// Create by TSMaster

VERSION ""

NS_ :

BS_:

BU_: Multiplexed

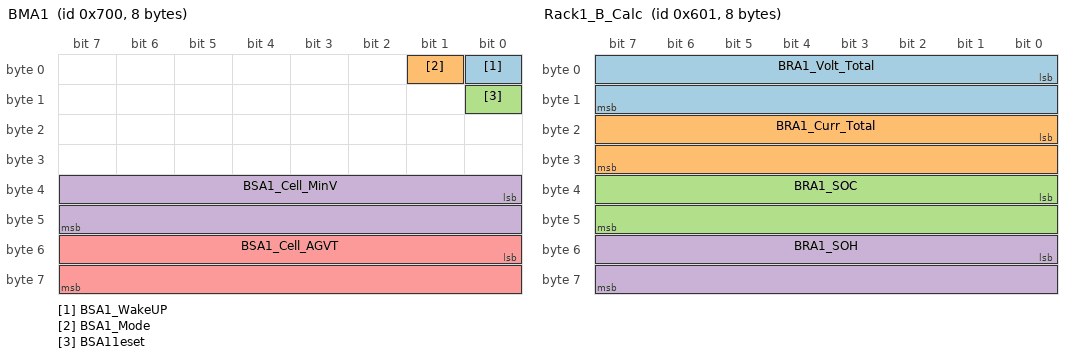
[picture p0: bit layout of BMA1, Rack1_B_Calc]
BO_ 1792 BMA1: 8 Vector__XXX
 SG_ BSA1_WakeUP : 0|1@1+ (1.0,0) [0.0|1.0] "" Vector__XXX
 SG_ BSA1_Mode : 1|1@1+ (1.0,0) [0.0|1.0] "" Vector__XXX
 SG_ BSA11eset : 8|1@1+ (1.0,0) [0.0|1.0] "" Vector__XXX
 SG_ BSA1_Cell_MinV : 32|16@1+ (0.001,0) [2.8|4.5] "" Vector__XXX
 SG_ BSA1_Cell_AGVT : 48|16@1- (0.1,0) [-40.0|100.0] "" Vector__XXX

BO_ 1537 Rack1_B_Calc: 8 Vector__XXX
 SG_ BRA1_Volt_Total : 0|16@1+ (0.1,0) [400.0|800.0] "" Vector__XXX
 SG_ BRA1_Curr_Total : 16|16@1- (0.1,0) [-500.0|500.0] "" Vector__XXX
 SG_ BRA1_SOC : 32|16@1+ (0.1,0) [0.0|120.0] "" Vector__XXX
 SG_ BRA1_SOH : 48|16@1+ (0.1,0) [0.0|100.0] "" Vector__XXX

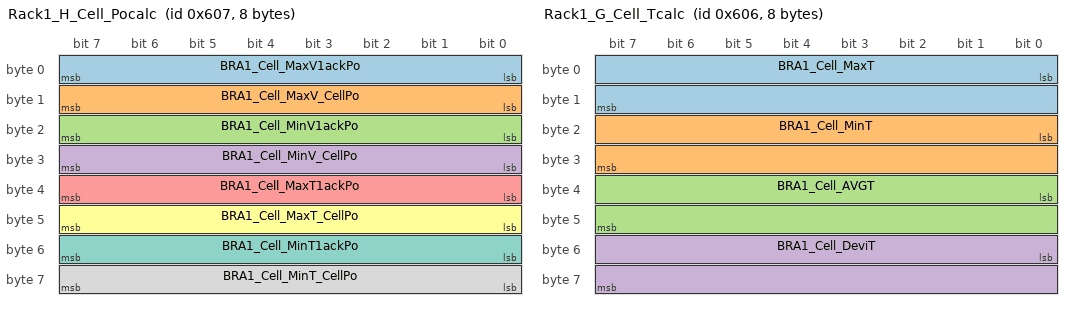
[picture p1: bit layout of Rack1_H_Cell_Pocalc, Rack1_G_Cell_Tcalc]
BO_ 1543 Rack1_H_Cell_Pocalc: 8 Vector__XXX
 SG_ BRA1_Cell_MaxV1ackPo : 0|8@1+ (1.0,0) [1.0|4.0] "" Vector__XXX
 SG_ BRA1_Cell_MaxV_CellPo : 8|8@1+ (1.0,0) [1.0|168.0] "" Vector__XXX
 SG_ BRA1_Cell_MinV1ackPo : 16|8@1+ (1.0,0) [1.0|4.0] "" Vector__XXX
 SG_ BRA1_Cell_MinV_CellPo : 24|8@1+ (1.0,0) [1.0|168.0] "" Vector__XXX
 SG_ BRA1_Cell_MaxT1ackPo : 32|8@1+ (1.0,0) [1.0|4.0] "" Vector__XXX
 SG_ BRA1_Cell_MaxT_CellPo : 40|8@1+ (1.0,0) [1.0|168.0] "" Vector__XXX
 SG_ BRA1_Cell_MinT1ackPo : 48|8@1+ (1.0,0) [1.0|4.0] "" Vector__XXX
 SG_ BRA1_Cell_MinT_CellPo : 56|8@1+ (1.0,0) [1.0|168.0] "" Vector__XXX

BO_ 1542 Rack1_G_Cell_Tcalc: 8 Vector__XXX
 SG_ BRA1_Cell_MaxT : 0|16@1- (0.1,0) [-40.0|100.0] "" Vector__XXX
 SG_ BRA1_Cell_MinT : 16|16@1- (0.1,0) [-40.0|100.0] "" Vector__XXX
 SG_ BRA1_Cell_AVGT : 32|16@1- (0.1,0) [-40.0|100.0] "" Vector__XXX
 SG_ BRA1_Cell_DeviT : 48|16@1+ (0.1,0) [-40.0|100.0] "" Vector__XXX

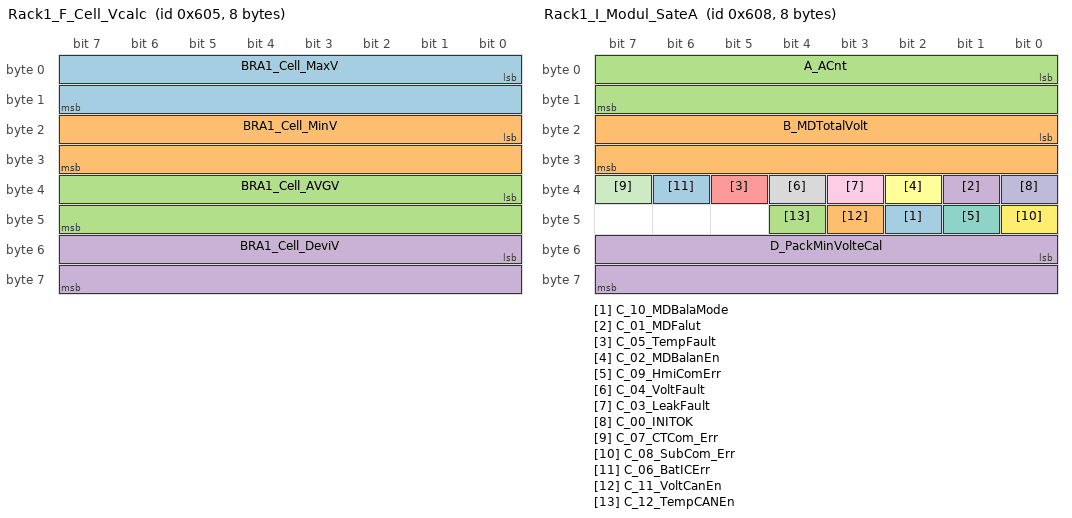
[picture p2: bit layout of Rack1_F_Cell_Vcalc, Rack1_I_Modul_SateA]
BO_ 1541 Rack1_F_Cell_Vcalc: 8 Vector__XXX
 SG_ BRA1_Cell_MaxV : 0|16@1+ (0.001,0) [2.8|4.5] "" Vector__XXX
 SG_ BRA1_Cell_MinV : 16|16@1+ (0.001,0) [2.8|4.5] "" Vector__XXX
 SG_ BRA1_Cell_AVGV : 32|16@1+ (0.001,0) [2.8|4.5] "" Vector__XXX
 SG_ BRA1_Cell_DeviV : 48|16@1+ (1.0,0) [0.0|500.0] "" Vector__XXX

BO_ 1544 Rack1_I_Modul_SateA: 8 Vector__XXX
 SG_ C_10_MDBalaMode : 42|1@1+ (0.1,0) [0|1] "F" Vector__XXX
 SG_ B_MDTotalVolt : 16|16@1+ (0.1,0) [40|100] "V" Vector__XXX
 SG_ A_ACnt : 0|16@1+ (1,0) [0|20] "Cnt" Vector__XXX
 SG_ C_01_MDFalut : 33|1@1+ (1,0) [0.0|1.0] "F" Vector__XXX
 SG_ C_05_TempFault : 37|1@1+ (1,0) [0.0|1.0] "F" Vector__XXX
 SG_ C_02_MDBalanEn : 34|1@1+ (1,0) [0.0|1.0] "F" Vector__XXX
 SG_ C_09_HmiComErr : 41|1@1+ (1,0) [0.0|1.0] "F" Vector__XXX
 SG_ C_04_VoltFault : 36|1@1+ (1,0) [0.0|1.0] "F" Vector__XXX
 SG_ C_03_LeakFault : 35|1@1+ (1,0) [0.0|1.0] "F" Vector__XXX
 SG_ C_00_INITOK : 32|1@1+ (1,0) [0.0|1] "F" Vector__XXX
 SG_ C_07_CTCom_Err : 39|1@1+ (1,0) [0.0|1.0] "F" Vector__XXX
 SG_ C_08_SubCom_Err : 40|1@1+ (1,0) [0.0|1.0] "F" Vector__XXX
 SG_ C_06_BatICErr : 38|1@1+ (1,0) [0|1] "F" Vector__XXX
 SG_ C_11_VoltCanEn : 43|1@1+ (1,0) [0|0] "F" Vector__XXX
 SG_ C_12_TempCANEn : 44|1@1+ (1,0) [0|1] "F" Vector__XXX
 SG_ D_PackMinVolteCal : 48|16@1+ (0.001,0) [2.8|4.8] "V" Vector__XXX

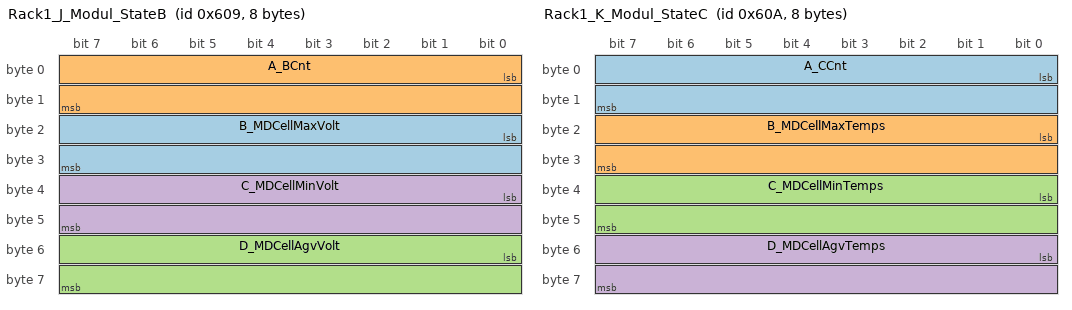
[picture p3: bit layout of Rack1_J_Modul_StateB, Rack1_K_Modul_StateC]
BO_ 1545 Rack1_J_Modul_StateB: 8 Vector__XXX
 SG_ B_MDCellMaxVolt : 16|16@1+ (0.001,0) [2.8|4.5] "V" Vector__XXX
 SG_ A_BCnt : 0|16@1+ (1,0) [0|20] "Cnt" Vector__XXX
 SG_ D_MDCellAgvVolt : 48|16@1+ (0.001,0) [2.8|4.5] "V" Vector__XXX
 SG_ C_MDCellMinVolt : 32|16@1+ (0.001,0) [2.8|4.5] "V" Vector__XXX

BO_ 1546 Rack1_K_Modul_StateC: 8 Vector__XXX
 SG_ A_CCnt : 0|16@1+ (1,0) [0|20] "Cnt" Vector__XXX
 SG_ B_MDCellMaxTemps : 16|16@1- (0.1,0) [-30|65] "deg" Vector__XXX
 SG_ C_MDCellMinTemps : 32|16@1- (0.1,0) [-30|0] "deg" Vector__XXX
 SG_ D_MDCellAgvTemps : 48|16@1- (0.1,0) [-30|65] "deg" Vector__XXX

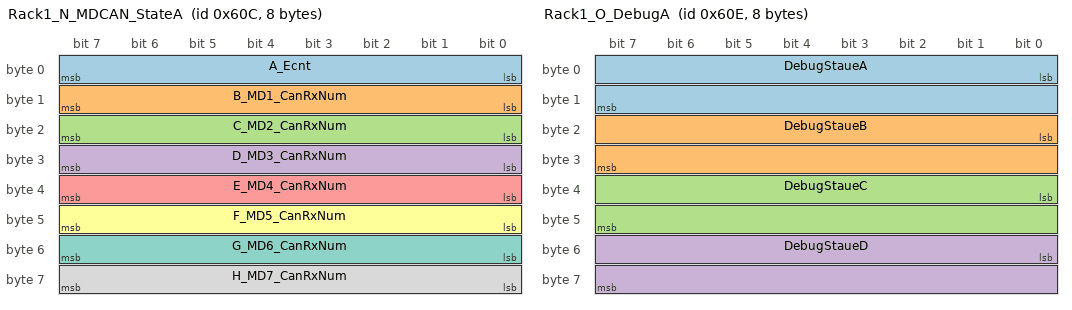
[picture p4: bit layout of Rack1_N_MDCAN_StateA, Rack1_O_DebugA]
BO_ 1548 Rack1_N_MDCAN_StateA: 8 Vector__XXX
 SG_ A_Ecnt : 0|8@1+ (1,0) [0|20] "Cnt" Vector__XXX
 SG_ B_MD1_CanRxNum : 8|8@1+ (1,0) [0|200] "Cnt" Vector__XXX
 SG_ C_MD2_CanRxNum : 16|8@1+ (1,0) [0|200] "Cnt" Vector__XXX
 SG_ D_MD3_CanRxNum : 24|8@1+ (1,0) [0|200] "Cnt" Vector__XXX
 SG_ E_MD4_CanRxNum : 32|8@1+ (1,0) [0|200] "Cnt" Vector__XXX
 SG_ F_MD5_CanRxNum : 40|8@1+ (1,0) [0|200] "Cnt" Vector__XXX
 SG_ G_MD6_CanRxNum : 48|8@1+ (1,0) [0|200] "Cnt" Vector__XXX
 SG_ H_MD7_CanRxNum : 56|8@1+ (1,0) [0|200] "Cnt" Vector__XXX

BO_ 1549 Rack1_N_MDCAN_StateB: 8 Vector__XXX
 SG_ A_Maincount : 0|16@1+ (1,0) [0|3000] "Cnt" Vector__XXX
 SG_ B_MainIsr1 : 16|16@1+ (1,0) [0|3000] "Cnt" Vector__XXX
 SG_ C_CTCanRx : 32|19@1+ (1,0) [0|3000] "Cnt" Vector__XXX
 SG_ D_MasterCanRx : 48|16@1+ (1,0) [0|0] "Cnt" Vector__XXX

BO_ 1550 Rack1_O_DebugA: 8 Vector__XXX
 SG_ DebugStaueA : 0|16@1+ (1,0) [0|0] "F" Vector__XXX
 SG_ DebugStaueB : 16|16@1+ (1,0) [0|3000] "F" Vector__XXX
 SG_ DebugStaueC : 32|16@1+ (1,0) [0|0] "F" Vector__XXX
 SG_ DebugStaueD : 48|16@1+ (1,0) [0|3000] "F" Vector__XXX

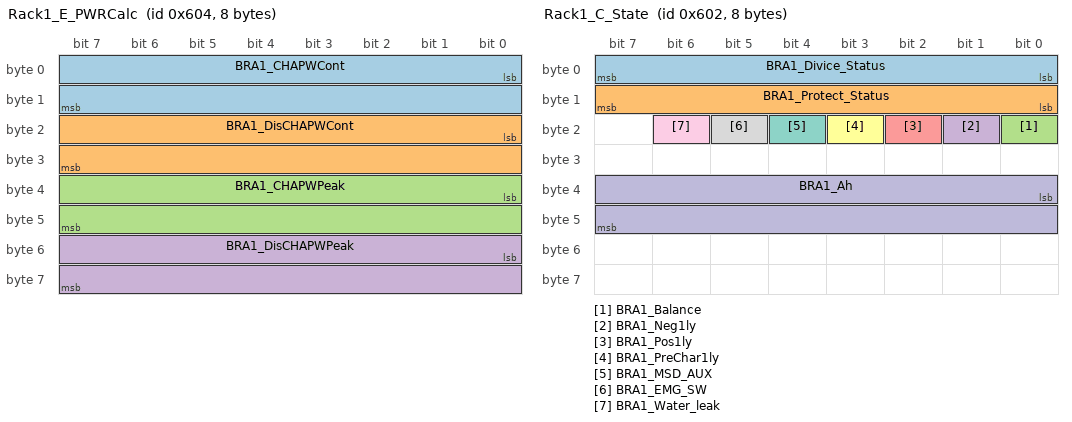
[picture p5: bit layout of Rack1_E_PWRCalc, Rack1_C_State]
BO_ 1540 Rack1_E_PWRCalc: 8 Vector__XXX
 SG_ BRA1_CHAPWCont : 0|16@1+ (0.1,0) [0.0|43.0] "" Vector__XXX
 SG_ BRA1_DisCHAPWCont : 16|16@1+ (0.1,0) [0.0|100.0] "" Vector__XXX
 SG_ BRA1_CHAPWPeak : 32|16@1+ (0.1,0) [0.0|60.0] "" Vector__XXX
 SG_ BRA1_DisCHAPWPeak : 48|16@1+ (0.1,0) [0.0|200.0] "" Vector__XXX

BO_ 1539 Rack1_D_ProtectState: 8 Vector__XXX
 SG_ BRA1_Wn_Dischager_OC : 0|1@1+ (1.0,0) [0.0|1.0] "" Vector__XXX
 SG_ BRA1_Wn_Chager_OC : 1|1@1+ (1.0,0) [0.0|1.0] "" Vector__XXX
 SG_ BRA1_Wn_SOC_OV : 2|1@1+ (1.0,0) [0.0|1.0] "" Vector__XXX
 SG_ BRA1_Wn_SOC_Un : 3|1@1+ (1.0,0) [0.0|1.0] "" Vector__XXX
 SG_ BRA1_Wn_OV : 4|1@1+ (1.0,0) [0.0|1.0] "" Vector__XXX
 SG_ BRA1_Wn_UV : 5|1@1+ (1.0,0) [0.0|1.0] "" Vector__XXX
 SG_ BRA1_Wn_Cell_OV : 6|1@1+ (1.0,0) [0.0|1.0] "" Vector__XXX
 SG_ BRA1_Wn_Cell_UV : 7|1@1+ (1.0,0) [0.0|1.0] "" Vector__XXX
 SG_ BRA1_Wn_Cell_UnbalV : 8|1@1+ (1.0,0) [0.0|1.0] "" Vector__XXX
 SG_ BRA1_Wn_DisCharger_Cell_OT : 9|1@1+ (1.0,0) [0.0|1.0] "" Vector__XXX
 SG_ BRA1_Wn_Charger_Cell_OT : 10|1@1+ (1.0,0) [0.0|1.0] "" Vector__XXX
 SG_ BRA1_Wn_DisCharger_Cell_UT : 11|1@1+ (1.0,0) [0.0|1.0] "" Vector__XXX
 SG_ BRA1_Wn_Charger_Cell_UT : 12|1@1+ (1.0,0) [0.0|1.0] "" Vector__XXX
 SG_ BRA1_Wn_Cell_UnbalT : 13|1@1+ (1.0,0) [0.0|1.0] "" Vector__XXX
 SG_ BRA1_Wn_Discharger_UnbaPWR : 14|1@1+ (1.0,0) [0.0|1.0] "" Vector__XXX
 SG_ BRA1_Wn_Charger_UnbaPWR : 15|1@1+ (1.0,0) [0.0|1.0] "" Vector__XXX
 SG_ BRA1_FLT_Dischager_OC : 16|1@1+ (1.0,0) [0.0|1.0] "" Vector__XXX
 SG_ BRA1_FLT_Chager_OC : 17|1@1+ (1.0,0) [0.0|1.0] "" Vector__XXX
 SG_ BRA1_FLT_SOC_OV : 18|1@1+ (1.0,0) [0.0|1.0] "" Vector__XXX
 SG_ BRA1_FLT_SOC_Un : 19|1@1+ (1.0,0) [0.0|1.0] "" Vector__XXX
 SG_ BRA1_FLT_OV : 20|1@1+ (1.0,0) [0.0|1.0] "" Vector__XXX
 SG_ BRA1_FLT_UV : 21|1@1+ (1.0,0) [0.0|1.0] "" Vector__XXX
 SG_ BRA1_FLT_Cell_OV : 22|1@1+ (1.0,0) [0.0|1.0] "" Vector__XXX
 SG_ BRA1_FLT_Cell_UV : 23|1@1+ (1.0,0) [0.0|1.0] "" Vector__XXX
 SG_ BRA1_FLT_Cell_UnbalV : 24|1@1+ (1.0,0) [0.0|1.0] "" Vector__XXX
 SG_ BRA1_FLT_DisCharger_Cell_OT : 25|1@1+ (1.0,0) [0.0|1.0] "" Vector__XXX
 SG_ BRA1_FLT_Charger_Cell_OT : 26|1@1+ (1.0,0) [0.0|1.0] "" Vector__XXX
 SG_ BRA1_FLT_DisCharger_Cell_UT : 27|1@1+ (1.0,0) [0.0|1.0] "" Vector__XXX
 SG_ BRA1_FLT_Charger_Cell_UT : 28|1@1+ (1.0,0) [0.0|1.0] "" Vector__XXX
 SG_ BRA1_FLT_Cell_UnbalT : 29|1@1+ (1.0,0) [0.0|1.0] "" Vector__XXX
 SG_ BRA1_FLT_Discharger_UnbaPWR : 30|1@1+ (1.0,0) [0.0|1.0] "" Vector__XXX
 SG_ BRA1_FLT_Charger_UnbaPWR : 31|1@1+ (1.0,0) [0.0|1.0] "" Vector__XXX
 SG_ BRA1_Prtct_Dischager_OC : 32|1@1+ (1.0,0) [0.0|1.0] "" Vector__XXX
 SG_ BRA1_Prtct_Chager_OC : 33|1@1+ (1.0,0) [0.0|1.0] "" Vector__XXX
 SG_ BRA1_Prtct_SOC_OV : 34|1@1+ (1.0,0) [0.0|1.0] "" Vector__XXX
 SG_ BRA1_Prtct_SOC_Un : 35|1@1+ (1.0,0) [0.0|1.0] "" Vector__XXX
 SG_ BRA1_Prtct_OV : 36|1@1+ (1.0,0) [0.0|1.0] "" Vector__XXX
 SG_ BRA1_Prtct_UV : 37|1@1+ (1.0,0) [0.0|1.0] "" Vector__XXX
 SG_ BRA1_Prtct_Cell_OV : 38|1@1+ (1.0,0) [0.0|1.0] "" Vector__XXX
 SG_ BRA1_Prtct_Cell_UV : 39|1@1+ (1.0,0) [0.0|1.0] "" Vector__XXX
 SG_ BRA1_Prtct_Cell_UnbalV : 40|1@1+ (1.0,0) [0.0|1.0] "" Vector__XXX
 SG_ BRA1_Prtct_DisCharger_Cell_OT : 41|1@1+ (1.0,0) [0.0|1.0] "" Vector__XXX
 SG_ BRA1_Prtct_Charger_Cell_OT : 42|1@1+ (1.0,0) [0.0|1.0] "" Vector__XXX
 SG_ BRA1_Prtct_DisCharger_Cell_UT : 43|1@1+ (1.0,0) [0.0|1.0] "" Vector__XXX
 SG_ BRA1_Prtct_Charger_Cell_UT : 44|1@1+ (1.0,0) [0.0|1.0] "" Vector__XXX
 SG_ BRA1_Prtct_Cell_UnbalT : 45|1@1+ (1.0,0) [0.0|1.0] "" Vector__XXX
 SG_ BRA1_Prtct_Discharger_UnbaPWR : 46|1@1+ (1.0,0) [0.0|1.0] "" Vector__XXX
 SG_ BRA1_Prtct_Charger_UnbaPWR : 47|1@1+ (1.0,0) [0.0|1.0] "" Vector__XXX
 SG_ BRA1_Prtct1ly_Err : 48|1@1+ (1.0,0) [0.0|1.0] "" Vector__XXX
 SG_ BRA1_Prtct_IN_COM_Err : 49|1@1+ (1.0,0) [0.0|1.0] "" Vector__XXX
 SG_ BRA1_Prtct_EX_COM_Err : 50|1@1+ (1.0,0) [0.0|1.0] "" Vector__XXX
 SG_ BRA1_Prtct_CT_COM_Err : 51|1@1+ (1.0,0) [0.0|1.0] "" Vector__XXX
 SG_ BRA1_Prtct_Water_Leak_Err : 52|1@1+ (1.0,0) [0.0|1.0] "" Vector__XXX
 SG_ BRA1_Prtct_EMS_SW_Err : 53|1@1+ (1.0,0) [0.0|1.0] "" Vector__XXX

BO_ 1538 Rack1_C_State: 8 Vector__XXX
 SG_ BRA1_Divice_Status : 0|8@1+ (1.0,0) [0.0|4.0] "" Vector__XXX
 SG_ BRA1_Protect_Status : 8|8@1+ (1.0,0) [0.0|4.0] "" Vector__XXX
 SG_ BRA1_Balance : 16|1@1+ (1.0,0) [0.0|1.0] "" Vector__XXX
 SG_ BRA1_Neg1ly : 17|1@1+ (1.0,0) [0.0|1.0] "" Vector__XXX
 SG_ BRA1_Pos1ly : 18|1@1+ (1.0,0) [0.0|1.0] "" Vector__XXX
 SG_ BRA1_PreChar1ly : 19|1@1+ (1.0,0) [0.0|1.0] "" Vector__XXX
 SG_ BRA1_MSD_AUX : 20|1@1+ (1.0,0) [0.0|1.0] "" Vector__XXX
 SG_ BRA1_EMG_SW : 21|1@1+ (1.0,0) [0.0|1.0] "" Vector__XXX
 SG_ BRA1_Water_leak : 22|1@1+ (1.0,0) [0.0|1.0] "" Vector__XXX
 SG_ BRA1_Ah : 32|16@1- (1.0,0) [-100.0|-100.0] "" Vector__XXX

BO_ 1296 Rack1_Unit: 8 Vector__XXX
 SG_ BRA1_Status_Urx : 3|0@1+ (1.0,0) [0.0|1.0] "" Vector__XXX
 SG_ BRA1_ComEn_Urx : 8|1@1+ (1.0,0) [0.0|1.0] "" Vector__XXX
 SG_ BRA11eset_Urx : 9|1@1+ (1.0,0) [0.0|1.0] "" Vector__XXX
 SG_ BRA1_Cell_AGVT_Urx : 32|16@1- (0.1,0) [-40.0|100.0] "" Vector__XXX
 SG_ BRA1_Cell_MinV_Urx : 48|16@1+ (0.001,0) [2.8|4.5] "" Vector__XXX

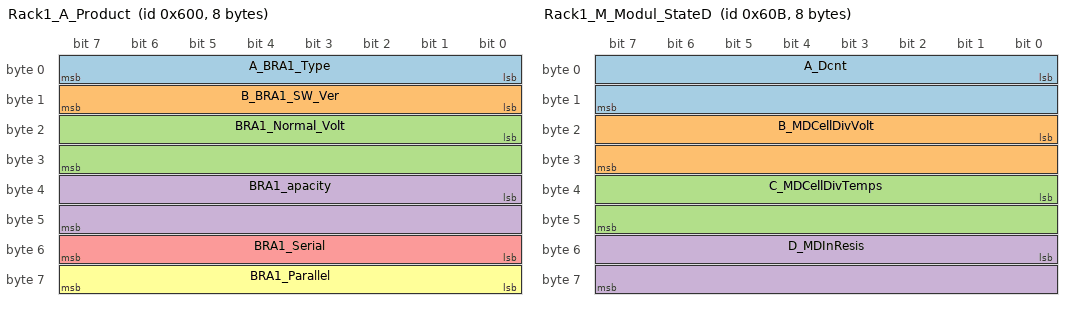
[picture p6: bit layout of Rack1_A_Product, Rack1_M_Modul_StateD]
BO_ 1536 Rack1_A_Product: 8 Vector__XXX
 SG_ A_BRA1_Type : 0|8@1+ (1.0,0) [0.0|10.0] "Type" Vector__XXX
 SG_ B_BRA1_SW_Ver : 8|8@1+ (0.1,0) [1.0|2.55] "Ver" Vector__XXX
 SG_ BRA1_Normal_Volt : 16|16@1+ (0.1,0) [400.0|800.0] "" Vector__XXX
 SG_ BRA1_apacity : 32|16@1+ (0.1,0) [30.0|500.0] "" Vector__XXX
 SG_ BRA1_Serial : 48|8@1+ (1.0,0) [0.0|200.0] "" Vector__XXX
 SG_ BRA1_Parallel : 56|8@1+ (1.0,0) [0.0|10.0] "" Vector__XXX

BO_ 1551 Rack1_O_DebugB: 8 Vector__XXX
 SG_ MB_00_WakeUp : 0|1@1+ (1,0) [0|1] "F" Vector__XXX
 SG_ MB_08_Reset : 8|1@1+ (1,0) [0|1] "F" Vector__XXX

BO_ 3221225472 VECTOR__INDEPENDENT_SIG_MSG: 0 Vector__XXX
 SG_ C_TempFaut : 37|1@1+ (1,0) [0|1] "F" Vector__XXX

BO_ 1547 Rack1_M_Modul_StateD: 8 Vector__XXX
 SG_ A_Dcnt : 0|16@1+ (1,0) [0|16] "Cnt" Vector__XXX
 SG_ B_MDCellDivVolt : 16|16@1+ (1,0) [0|500] "mV" Vector__XXX
 SG_ C_MDCellDivTemps : 32|16@1+ (0.1,0) [0|20] "deg" Vector__XXX
 SG_ D_MDInResis : 48|16@1+ (1,0) [0|5000] "mOhm" Vector__XXX

CM_ SG_ 1544 A_ACnt "배열 카운터";
